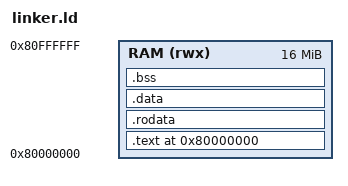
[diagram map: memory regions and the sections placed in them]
OUTPUT_ARCH(riscv)
ENTRY(_start)

MEMORY
{
    RAM (rwx) : ORIGIN = 0x80000000, LENGTH = 16M
}

PHDRS
{
    text PT_LOAD FLAGS(5);
    data PT_LOAD FLAGS(6);
}

SECTIONS
{
    . = ORIGIN(RAM);

    .text : ALIGN(4)
    {
        KEEP(*(.text.start))
        *(.text .text.*)
    } > RAM :text

    .rodata : ALIGN(8)
    {
        *(.srodata .srodata.*)
        *(.rodata .rodata.*)
        *(.eh_frame .eh_frame.*)
    } > RAM :text

    .data : ALIGN(8)
    {
        __global_pointer$ = . + 0x800;
        *(.sdata .sdata.*)
        *(.data .data.*)
        *(.init_array .init_array.*)
        *(.fini_array .fini_array.*)
    } > RAM :data

    .bss (NOLOAD) : ALIGN(8)
    {
        __bss_start = .;
        *(.sbss .sbss.*)
        *(.bss .bss.*)
        *(COMMON)
        . = ALIGN(8);
        __bss_end = .;
    } > RAM :data

    . = ALIGN(16);
    __stack_top = ORIGIN(RAM) + LENGTH(RAM);

    /DISCARD/ :
    {
        *(.comment)
    }
}
